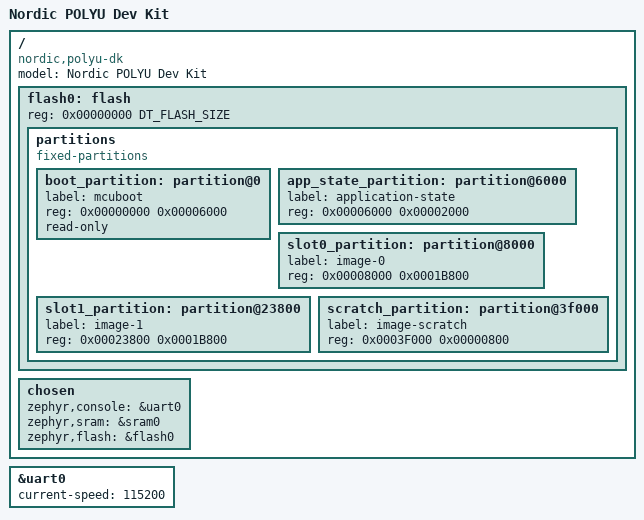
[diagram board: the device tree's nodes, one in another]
/*
 * Copyright (c) 2017 Trylong Limited
 *
 * SPDX-License-Identifier: Apache-2.0
 */

/dts-v1/;
#include <nordic/nrf51822.dtsi>

/ {
	model = "Nordic POLYU Dev Kit";
	compatible = "nordic,polyu-dk", "nordic,nrf51822-qfaa",
		     "nordic,nrf51822";

	flash0: flash {
		reg = <0x00000000 DT_FLASH_SIZE>;

		partitions {
			compatible = "fixed-partitions";
			#address-cells = <1>;
			#size-cells = <1>;

			boot_partition: partition@0 {
				label = "mcuboot";
				reg = <0x00000000 0x00006000>;
				read-only;
			};
			app_state_partition: partition@6000 {
				label = "application-state";
				reg = <0x00006000 0x00002000>;
			};
			slot0_partition: partition@8000 {
				label = "image-0";
				reg = <0x00008000 0x0001B800>;
			};
			slot1_partition: partition@23800 {
				label = "image-1";
				reg = <0x00023800 0x0001B800>;
			};
			scratch_partition: partition@3f000 {
				label = "image-scratch";
				reg = <0x0003F000 0x00000800>;
			};
		};
	};

	chosen {
		zephyr,console = &uart0;
		zephyr,sram = &sram0;
		zephyr,flash = &flash0;
	//	zephyr,code-partition = &slot0_partition;
	};
};

&uart0 {
	current-speed = <115200>;
	status = "ok";
};
